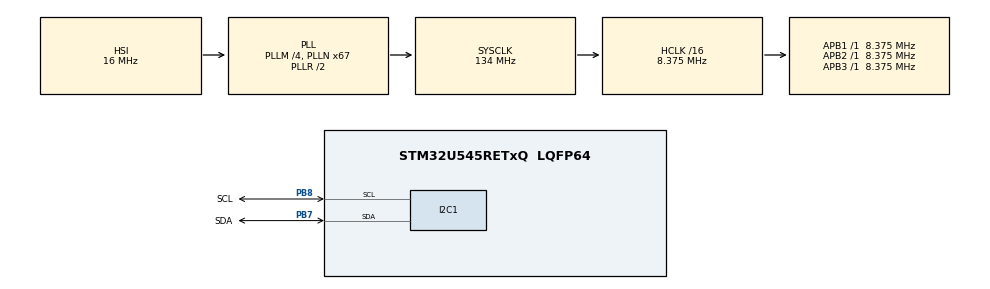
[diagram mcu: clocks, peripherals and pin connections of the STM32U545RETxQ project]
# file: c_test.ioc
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CORTEX_M33_NS.userName=CORTEX_M33
GPDMA1.DATAHANDLING_GPDMACH0=ENABLE
GPDMA1.DATAHANDLING_GPDMACH1=ENABLE
GPDMA1.DESTINC_GPDMACH1=DMA_DINC_INCREMENTED
GPDMA1.DIRECTION_GPDMACH0=DMA_MEMORY_TO_PERIPH
GPDMA1.IPHANDLE_GPDMACH0-SIMPLEREQUEST_GPDMACH0=__NULL
GPDMA1.IPHANDLE_GPDMACH1-SIMPLEREQUEST_GPDMACH1=__NULL
GPDMA1.REQUEST_GPDMACH0=GPDMA1_REQUEST_I2C1_TX
GPDMA1.REQUEST_GPDMACH1=GPDMA1_REQUEST_I2C1_RX
GPDMA1.SRCINC_GPDMACH0=DMA_SINC_INCREMENTED
GPDMA1.TRANSFERALLOCATEDPORTDEST_GPDMACH0=DMA_DEST_ALLOCATED_PORT0
GPDMA1.TRANSFERALLOCATEDPORTDEST_GPDMACH1=DMA_DEST_ALLOCATED_PORT1
GPDMA1.TRANSFERALLOCATEDPORTSRC_GPDMACH0=DMA_SRC_ALLOCATED_PORT1
I2C1.Timing=0x00201F2E
Mcu.Family=STM32U5
Mcu.Name=STM32U545RETxQ
Mcu.Package=LQFP64
NVIC.GPDMA1_Channel0_IRQn=true\:0\:0\:false\:false\:true\:false\:true\:true
NVIC.GPDMA1_Channel1_IRQn=true\:0\:0\:false\:false\:true\:false\:true\:true
NVIC.I2C1_ER_IRQn=true\:0\:0\:false\:false\:true\:true\:true\:true
NVIC.I2C1_EV_IRQn=true\:0\:0\:false\:false\:true\:true\:true\:true
NVIC.PriorityGroup=NVIC_PRIORITYGROUP_4
PA13\ (JTMS/SWDIO).Mode=Serial_Wire
PA13\ (JTMS/SWDIO).Signal=DEBUG_JTMS-SWDIO
PA14\ (JTCK/SWCLK).Mode=Serial_Wire
PA14\ (JTCK/SWCLK).Signal=DEBUG_JTCK-SWCLK
PB7.GPIO_Label=SDA
PB7.Mode=I2C
PB7.Signal=I2C1_SDA
PB8.GPIO_Label=SCL
PB8.Mode=I2C
PB8.Signal=I2C1_SCL
PWR.PowerMode=PWR_SMPS_SUPPLY
ProjectManager.HeapSize=0x200
ProjectManager.StackSize=0x400
ProjectManager.TargetToolchain=CMake
RCC.ADCFreq_Value=16000000
RCC.AHBCLKDivider=RCC_SYSCLK_DIV16
RCC.AHBFreq_Value=8375000
RCC.APB1Freq_Value=8375000
RCC.APB1TimFreq_Value=8375000
RCC.APB2Freq_Value=8375000
RCC.APB2TimFreq_Value=8375000
RCC.APB3Freq_Value=8375000
RCC.CortexFreq_Value=8375000
RCC.DACCLockSelectionVirtual=RCC_DAC1CLKSOURCE_LSI
RCC.DACCLockSelectionVirtualString=RCC_DAC1CLKSOURCE_LSI
RCC.EPOD_VALUE=16000000
RCC.HCLKFreq_Value=8375000
RCC.HSE_VALUE=16000000
RCC.HSI48_VALUE=48000000
RCC.HSI_VALUE=16000000
RCC.LSE_VALUE=32768
RCC.LSIDIV_VALUE=32000
RCC.MSI_VALUE=4000000
RCC.PLLM=4
RCC.PLLN=67
RCC.PLLSourceVirtual=RCC_PLLSOURCE_HSI
RCC.SYSCLKFreq_VALUE=134000000
RCC.SYSCLKSource=RCC_SYSCLKSOURCE_PLLCLK
RCC.USBFreq_Value=48000000
RCC.VCOOutputFreq_Value=268000000
VP_GPDMA1_VS_GPDMACH0.Mode=SIMPLEREQUEST_GPDMACH0
VP_GPDMA1_VS_GPDMACH1.Mode=SIMPLEREQUEST_GPDMACH1
VP_ICACHE_VS_ICACHE.Mode=DefaultMode
VP_LPBAMQUEUE_VS_QUEUE.Mode=QUEUEMODE
VP_LPBAM_VS_SIG1.Mode=SmartRun
VP_LPBAM_VS_SIG4.Mode=LPDMA1
VP_MEMORYMAP_VS_MEMORYMAP.Mode=CurAppReg
VP_PWR_VS_LPOM.Mode=PowerOptimisation
VP_PWR_VS_SECSignals.Mode=Security/Privilege
board=custom

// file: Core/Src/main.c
/* USER CODE BEGIN Header */
/**
 ******************************************************************************
 * @file           : main.c
 * @brief          : Main program body
 ******************************************************************************
 * @attention
 *
 * Copyright (c) 2024 STMicroelectronics.
 * All rights reserved.
 *
 * This software is licensed under terms that can be found in the LICENSE file
 * in the root directory of this software component.
 * If no LICENSE file comes with this software, it is provided AS-IS.
 *
 ******************************************************************************
 */
/* USER CODE END Header */
#include "main.h"

/* USER CODE BEGIN Includes */
#include "SEGGER_RTT.h"
#include "aem10900.h"
#include "aem10900_reg.h"
#include "stm32u5xx_hal.h"
#include "stm32u5xx_hal_def.h"
#include "stm32u5xx_hal_gpio.h"
#include "stm32u5xx_hal_i2c.h"
#include "stm32u5xx_hal_pwr_ex.h"
#include <stdint.h>
#include <stdio.h>
/* USER CODE END Includes */

I2C_HandleTypeDef hi2c1;
DMA_HandleTypeDef handle_GPDMA1_Channel1;
DMA_HandleTypeDef handle_GPDMA1_Channel0;

/* USER CODE BEGIN PV */
bool aem_i2c_tx_cplt_flag = false;
bool aem_i2c_rx_cplt_flag = false;
/* USER CODE END PV */

void SystemClock_Config(void);
static void SystemPower_Config(void);
static void MX_GPIO_Init(void);
static void MX_GPDMA1_Init(void);
static void MX_ICACHE_Init(void);
static void MX_I2C1_Init(void);
/* USER CODE BEGIN PFP */
aem10900_err_t aem10900_i2c_read_regs(uint8_t dev_adr, uint8_t start_reg_adr,
                                      uint8_t *buf, size_t length);
aem10900_err_t aem10900_i2c_write_regs(uint8_t dev_adr, uint8_t start_reg_adr,
                                       uint8_t *buf, size_t length);
void aem10900_log(char *msg, bool is_err, bool has_int_arg, uint32_t arg);
/* USER CODE END PFP */

int main(void) {

  /* MCU Configuration--------------------------------------------------------*/

  /* Reset of all peripherals, Initializes the Flash interface and the Systick.
   */
  HAL_Init();

  /* USER CODE BEGIN Init */
  SEGGER_RTT_printf(0, "Starting up AEM10900 Test Application\r\n");
  /* USER CODE END Init */

  /* Configure the system clock */
  SystemClock_Config();

  /* Configure the System Power */
  SystemPower_Config();

  /* Initialize all configured peripherals */
  MX_GPIO_Init();
  MX_GPDMA1_Init();
  MX_ICACHE_Init();
  MX_I2C1_Init();
  /* USER CODE BEGIN 2 */

  // Initialize device struct
  aem10900_err_t err = E_AEM10900_SUCCESS;
  struct aem10900_h dev = {
      .i2c_read_regs = aem10900_i2c_read_regs,
      .i2c_write_regs = aem10900_i2c_write_regs,
      .log = aem10900_log,
      .dev_adr = 0x41 << 1,
  };

  // Load default configuration
  err = aem10900_init_struct_with_reset_val(&dev.conf);
  if (err) {
    Error_Handler();
  }

  // Change desired configurations
  {
    dev.conf.mpptcfg.ratio = AEM10900_RATIO_R_80;          // set 80% MPPT ratio
    dev.conf.mpptcfg.timing = AEM10900_TIMING_T_4MS_512MS; // 4ms - 512ms
    dev.conf.vovdis.thresh = (uint8_t)((3.00 - 0.50625) / 0.05625); // 3V
    dev.conf.vovch.thresh = (uint8_t)((4.20 - 1.2375) / 0.05625);   // 4.2V
    // dev.conf.tempcold; // no THERMAL resistor mounted
    // dev.conf.temphot; // no THERMAL resistor mounted
    dev.conf.pwr.keepalen = true; // enable keepalive
    dev.conf.pwr.hpen = true;     // enable automatic high-power mode
    dev.conf.pwr.tmonen = false;  // disable temperature monitoring
    dev.conf.pwr.stochdis = true; // allow charging of battery
    dev.conf.sleep.en = false;    // disable sleep, even if src voltage is low
    // dev.conf.sleep.srcthresh; // sleep is disabled
    dev.conf.stomon.rate =
        AEM10900_RATE_R_1024MS; // read battery voltage every second
    dev.conf.apm.en = true;     // enable the APM mode
    dev.conf.apm.mode = AEM10900_MODE_POWER_METER; // and set it to power mode
    dev.conf.apm.window =
        AEM10900_WINDOW_W_128MS_256MS; // computation window 128ms, refresh rate
                                       // 64ms
    dev.conf.irqen.i2crdy =
        false; // disable (as enabled on boot). when IRQ is fired, IC is ready
    dev.conf.irqen.vovdis = false;
    dev.conf.irqen.vovch = false;
    dev.conf.irqen.srcthresh = false;
    dev.conf.irqen.temp = false;
    dev.conf.irqen.apmdone = false;
    dev.conf.ctrl.update = AEM10900_UPDATE_I2C; // Use I2C configuration
  }
  HAL_Delay(500);
  err = aem10900_init(&dev);
  if (err != E_AEM10900_SUCCESS) {
    SEGGER_RTT_printf(0, "Failed to init AEM10900 with %d\r\n", err);
    Error_Handler();
  }

  /* USER CODE END 2 */

  /* Infinite loop */
  /* USER CODE BEGIN WHILE */
  while (1) {
    float res = 0;
    aem10900_read_battery_voltage(&dev, &res);
    char buf[100] = {0};
    snprintf(buf, sizeof(buf), "Battery voltage is %f\r\n", res);
    SEGGER_RTT_WriteString(0, buf);
    HAL_Delay(5000);

    /* USER CODE END WHILE */

  }
}

void SystemClock_Config(void) {
  RCC_OscInitTypeDef RCC_OscInitStruct = {0};
  RCC_ClkInitTypeDef RCC_ClkInitStruct = {0};

  /** Configure the main internal regulator output voltage
   */
  if (HAL_PWREx_ControlVoltageScaling(PWR_REGULATOR_VOLTAGE_SCALE1) != HAL_OK) {
    Error_Handler();
  }

  /** Initializes the CPU, AHB and APB buses clocks
   */
  RCC_OscInitStruct.OscillatorType = RCC_OSCILLATORTYPE_HSI;
  RCC_OscInitStruct.HSIState = RCC_HSI_ON;
  RCC_OscInitStruct.HSICalibrationValue = RCC_HSICALIBRATION_DEFAULT;
  RCC_OscInitStruct.PLL.PLLState = RCC_PLL_ON;
  RCC_OscInitStruct.PLL.PLLSource = RCC_PLLSOURCE_HSI;
  RCC_OscInitStruct.PLL.PLLMBOOST = RCC_PLLMBOOST_DIV1;
  RCC_OscInitStruct.PLL.PLLM = 4;
  RCC_OscInitStruct.PLL.PLLN = 67;
  RCC_OscInitStruct.PLL.PLLP = 2;
  RCC_OscInitStruct.PLL.PLLQ = 2;
  RCC_OscInitStruct.PLL.PLLR = 2;
  RCC_OscInitStruct.PLL.PLLRGE = RCC_PLLVCIRANGE_0;
  RCC_OscInitStruct.PLL.PLLFRACN = 0;
  if (HAL_RCC_OscConfig(&RCC_OscInitStruct) != HAL_OK) {
    Error_Handler();
  }

  /** Initializes the CPU, AHB and APB buses clocks
   */
  RCC_ClkInitStruct.ClockType = RCC_CLOCKTYPE_HCLK | RCC_CLOCKTYPE_SYSCLK |
                                RCC_CLOCKTYPE_PCLK1 | RCC_CLOCKTYPE_PCLK2 |
                                RCC_CLOCKTYPE_PCLK3;
  RCC_ClkInitStruct.SYSCLKSource = RCC_SYSCLKSOURCE_PLLCLK;
  RCC_ClkInitStruct.AHBCLKDivider = RCC_SYSCLK_DIV16;
  RCC_ClkInitStruct.APB1CLKDivider = RCC_HCLK_DIV1;
  RCC_ClkInitStruct.APB2CLKDivider = RCC_HCLK_DIV1;
  RCC_ClkInitStruct.APB3CLKDivider = RCC_HCLK_DIV1;

  if (HAL_RCC_ClockConfig(&RCC_ClkInitStruct, FLASH_LATENCY_0) != HAL_OK) {
    Error_Handler();
  }
}

/**
 * @brief Power Configuration
 * @retval None
 */
static void SystemPower_Config(void) {

  /*
   * Switch to SMPS regulator instead of LDO
   */
  if (HAL_PWREx_ConfigSupply(PWR_SMPS_SUPPLY) != HAL_OK) {
    Error_Handler();
  }
}

static void MX_GPDMA1_Init(void) {

  /* Peripheral clock enable */
  __HAL_RCC_GPDMA1_CLK_ENABLE();

  /* GPDMA1 interrupt Init */
  HAL_NVIC_SetPriority(GPDMA1_Channel0_IRQn, 0, 0);
  HAL_NVIC_EnableIRQ(GPDMA1_Channel0_IRQn);
  HAL_NVIC_SetPriority(GPDMA1_Channel1_IRQn, 0, 0);
  HAL_NVIC_EnableIRQ(GPDMA1_Channel1_IRQn);

}

static void MX_I2C1_Init(void) {

  hi2c1.Instance = I2C1;
  hi2c1.Init.Timing = 0x00201F2E;
  hi2c1.Init.OwnAddress1 = 0;
  hi2c1.Init.AddressingMode = I2C_ADDRESSINGMODE_7BIT;
  hi2c1.Init.DualAddressMode = I2C_DUALADDRESS_DISABLE;
  hi2c1.Init.OwnAddress2 = 0;
  hi2c1.Init.OwnAddress2Masks = I2C_OA2_NOMASK;
  hi2c1.Init.GeneralCallMode = I2C_GENERALCALL_DISABLE;
  hi2c1.Init.NoStretchMode = I2C_NOSTRETCH_DISABLE;
  if (HAL_I2C_Init(&hi2c1) != HAL_OK) {
    Error_Handler();
  }

  /** Configure Analogue filter
   */
  if (HAL_I2CEx_ConfigAnalogFilter(&hi2c1, I2C_ANALOGFILTER_ENABLE) != HAL_OK) {
    Error_Handler();
  }

  /** Configure Digital filter
   */
  if (HAL_I2CEx_ConfigDigitalFilter(&hi2c1, 0) != HAL_OK) {
    Error_Handler();
  }
}

static void MX_ICACHE_Init(void) {

  /** Enable instruction cache (default 2-ways set associative cache)
   */
  if (HAL_ICACHE_Enable() != HAL_OK) {
    Error_Handler();
  }
}

static void MX_GPIO_Init(void) {
  GPIO_InitTypeDef GPIO_InitStruct = {0};

  /* GPIO Ports Clock Enable */
  __HAL_RCC_GPIOC_CLK_ENABLE();
  __HAL_RCC_GPIOH_CLK_ENABLE();
  __HAL_RCC_GPIOA_CLK_ENABLE();
  __HAL_RCC_GPIOB_CLK_ENABLE();
  __HAL_RCC_GPIOD_CLK_ENABLE();

  /*Configure GPIO pins : PC13 PC14 PC15 PC0
                           PC1 PC2 PC3 PC6
                           PC7 PC8 PC9 PC10
                           PC11 PC12 */
  GPIO_InitStruct.Pin = GPIO_PIN_13 | GPIO_PIN_14 | GPIO_PIN_15 | GPIO_PIN_0 |
                        GPIO_PIN_1 | GPIO_PIN_2 | GPIO_PIN_3 | GPIO_PIN_6 |
                        GPIO_PIN_7 | GPIO_PIN_8 | GPIO_PIN_9 | GPIO_PIN_10 |
                        GPIO_PIN_11 | GPIO_PIN_12;
  GPIO_InitStruct.Mode = GPIO_MODE_ANALOG;
  GPIO_InitStruct.Pull = GPIO_NOPULL;
  HAL_GPIO_Init(GPIOC, &GPIO_InitStruct);

  /*Configure GPIO pins : PH0 PH1 PH3 */
  GPIO_InitStruct.Pin = GPIO_PIN_0 | GPIO_PIN_1 | GPIO_PIN_3;
  GPIO_InitStruct.Mode = GPIO_MODE_ANALOG;
  GPIO_InitStruct.Pull = GPIO_NOPULL;
  HAL_GPIO_Init(GPIOH, &GPIO_InitStruct);

  /*Configure GPIO pins : PA0 PA1 PA2 PA3
                           PA4 PA5 PA6 PA7
                           PA8 PA9 PA10 PA11
                           PA12 PA15 */
  GPIO_InitStruct.Pin = GPIO_PIN_0 | GPIO_PIN_1 | GPIO_PIN_2 | GPIO_PIN_3 |
                        GPIO_PIN_4 | GPIO_PIN_5 | GPIO_PIN_6 | GPIO_PIN_7 |
                        GPIO_PIN_8 | GPIO_PIN_9 | GPIO_PIN_10 | GPIO_PIN_11 |
                        GPIO_PIN_12 | GPIO_PIN_15;
  GPIO_InitStruct.Mode = GPIO_MODE_ANALOG;
  GPIO_InitStruct.Pull = GPIO_NOPULL;
  HAL_GPIO_Init(GPIOA, &GPIO_InitStruct);

  /*Configure GPIO pins : PB0 PB1 PB2 PB10
                           PB13 PB14 PB15 PB3
                           PB4 PB5 PB6 */
  GPIO_InitStruct.Pin = GPIO_PIN_0 | GPIO_PIN_1 | GPIO_PIN_2 | GPIO_PIN_10 |
                        GPIO_PIN_13 | GPIO_PIN_14 | GPIO_PIN_15 | GPIO_PIN_3 |
                        GPIO_PIN_4 | GPIO_PIN_5 | GPIO_PIN_6;
  GPIO_InitStruct.Mode = GPIO_MODE_ANALOG;
  GPIO_InitStruct.Pull = GPIO_NOPULL;
  HAL_GPIO_Init(GPIOB, &GPIO_InitStruct);

  /*Configure GPIO pin : PD2 */
  GPIO_InitStruct.Pin = GPIO_PIN_2;
  GPIO_InitStruct.Mode = GPIO_MODE_ANALOG;
  GPIO_InitStruct.Pull = GPIO_NOPULL;
  HAL_GPIO_Init(GPIOD, &GPIO_InitStruct);

}

/* USER CODE BEGIN 4 */
aem10900_err_t aem10900_i2c_write_regs(uint8_t dev_adr, uint8_t start_reg_adr,
                                       uint8_t *buf, size_t length) {

  uint32_t timeout_counter = 134000; // 10ms

  // Transmit data
  aem_i2c_tx_cplt_flag = false;
  HAL_StatusTypeDef ret =
      HAL_I2C_Mem_Write_DMA(&hi2c1, dev_adr, start_reg_adr, 1, buf, length);
  while (!aem_i2c_tx_cplt_flag && --timeout_counter) {
    __asm__("nop");
  }

  if (timeout_counter == 0) {
    return E_AEM10900_COM_ERR;
  }

  if (ret == HAL_OK) {
    return E_AEM10900_SUCCESS;
  }

  return E_AEM10900_COM_ERR;
}

aem10900_err_t aem10900_i2c_read_regs(uint8_t dev_adr, uint8_t start_reg_adr,
                                      uint8_t *buf, size_t length) {

  uint32_t timeout_counter = 134000; // 10ms

  aem_i2c_rx_cplt_flag = false;
  HAL_StatusTypeDef ret =
      HAL_I2C_Mem_Read_DMA(&hi2c1, dev_adr, start_reg_adr, 1, buf, length);
  while (!aem_i2c_rx_cplt_flag && --timeout_counter) {
    __asm__("nop");
  }

  if (timeout_counter == 0) {
    return E_AEM10900_COM_ERR;
  }

  if (ret == HAL_OK) {
    return E_AEM10900_SUCCESS;
  }

  return E_AEM10900_COM_ERR;
}

void aem10900_log(char *msg, bool is_err, bool has_int_arg, uint32_t arg) {
  char *format_str =
      is_err
          ? (has_int_arg ? "[ERR] %s, with value: 0x%02x\r\n" : "[ERR] %s\r\n")
          : (has_int_arg ? "[INF] %s, with value: 0x%02x\r\n" : "[INF] %s\r\n");
  if (has_int_arg) {
    SEGGER_RTT_printf(0, format_str, msg, arg);
  } else {
    SEGGER_RTT_printf(0, format_str, msg);
  }
}

void HAL_I2C_MemTxCpltCallback(I2C_HandleTypeDef *hi2c) {
  if (hi2c == &hi2c1) {
    aem_i2c_tx_cplt_flag = true;
  }
}

void HAL_I2C_MemRxCpltCallback(I2C_HandleTypeDef *hi2c) {
  if (hi2c == &hi2c1) {
    aem_i2c_rx_cplt_flag = true;
  }
}
/* USER CODE END 4 */

void Error_Handler(void) {
  __disable_irq();
  while (1) {
  }
}

#ifdef USE_FULL_ASSERT
/**
 * @brief  Reports the name of the source file and the source line number
 *         where the assert_param error has occurred.
 * @param  file: pointer to the source file name
 * @param  line: assert_param error line source number
 * @retval None
 */
void assert_failed(uint8_t *file, uint32_t line) {
  /* USER CODE BEGIN 6 */
  /* User can add his own implementation to report the file name and line
     number, ex: printf("Wrong parameters value: file %s on line %d\r\n", file,
     line) */
  /* USER CODE END 6 */
}
#endif /* USE_FULL_ASSERT */
